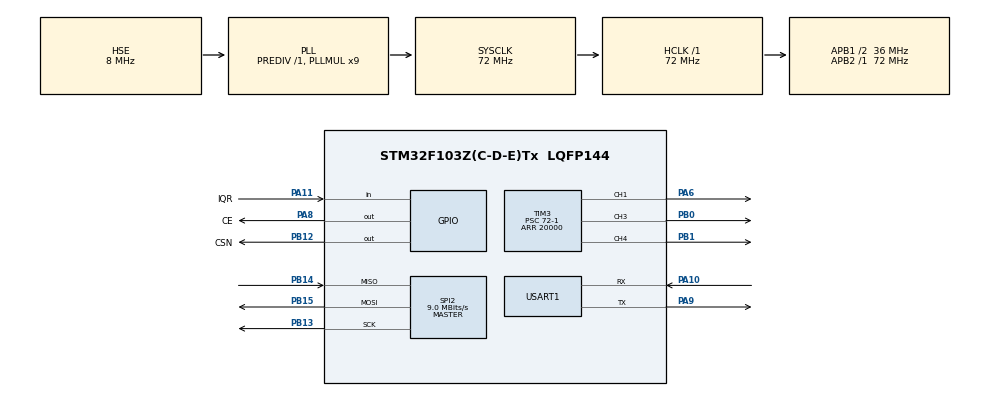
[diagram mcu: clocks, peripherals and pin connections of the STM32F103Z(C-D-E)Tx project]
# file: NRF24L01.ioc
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Mcu.Family=STM32F1
Mcu.Name=STM32F103Z(C-D-E)Tx
Mcu.Package=LQFP144
NVIC.PriorityGroup=NVIC_PRIORITYGROUP_4
OSC_IN.Mode=HSE-External-Oscillator
OSC_IN.Signal=RCC_OSC_IN
OSC_OUT.Mode=HSE-External-Oscillator
OSC_OUT.Signal=RCC_OSC_OUT
PA10.GPIO_PuPd=GPIO_NOPULL
PA10.Mode=Asynchronous
PA10.Signal=USART1_RX
PA11.GPIO_Label=IQR
PA11.Signal=GPIO_Input
PA13.Mode=Serial_Wire
PA13.Signal=SYS_JTMS-SWDIO
PA14.Mode=Serial_Wire
PA14.Signal=SYS_JTCK-SWCLK
PA6.Signal=S_TIM3_CH1
PA8.GPIO_Label=CE
PA8.GPIO_Speed=GPIO_SPEED_FREQ_HIGH
PA8.PinState=GPIO_PIN_SET
PA8.Signal=GPIO_Output
PA9.Mode=Asynchronous
PA9.Signal=USART1_TX
PB0.Signal=S_TIM3_CH3
PB1.Signal=S_TIM3_CH4
PB12.GPIO_Label=CSN
PB12.GPIO_ModeDefaultOutputPP=GPIO_MODE_OUTPUT_PP
PB12.GPIO_Speed=GPIO_SPEED_FREQ_HIGH
PB12.PinState=GPIO_PIN_SET
PB12.Signal=GPIO_Output
PB13.GPIO_Speed=GPIO_SPEED_FREQ_HIGH
PB13.Mode=Full_Duplex_Master
PB13.Signal=SPI2_SCK
PB14.GPIO_PuPd=GPIO_PULLUP
PB14.Mode=Full_Duplex_Master
PB14.Signal=SPI2_MISO
PB15.GPIO_Mode=GPIO_MODE_AF_PP
PB15.Mode=Full_Duplex_Master
PB15.Signal=SPI2_MOSI
ProjectManager.HeapSize=0x200
ProjectManager.StackSize=0x400
ProjectManager.TargetToolchain=MDK-ARM V5
RCC.ADCPresc=RCC_ADCPCLK2_DIV6
RCC.AHBFreq_Value=72000000
RCC.APB1CLKDivider=RCC_HCLK_DIV2
RCC.APB1Freq_Value=36000000
RCC.APB1TimFreq_Value=72000000
RCC.APB2Freq_Value=72000000
RCC.APB2TimFreq_Value=72000000
RCC.HCLKFreq_Value=72000000
RCC.PLLMUL=RCC_PLL_MUL9
RCC.PLLSourceVirtual=RCC_PLLSOURCE_HSE
RCC.SYSCLKFreq_VALUE=72000000
RCC.SYSCLKSource=RCC_SYSCLKSOURCE_PLLCLK
RCC.USBFreq_Value=72000000
SH.S_TIM3_CH1.0=TIM3_CH1,PWM Generation1 CH1
SH.S_TIM3_CH3.0=TIM3_CH3,PWM Generation3 CH3
SH.S_TIM3_CH4.0=TIM3_CH4,PWM Generation4 CH4
SPI2.BaudRatePrescaler=SPI_BAUDRATEPRESCALER_4
SPI2.CalculateBaudRate=9.0 MBits/s
SPI2.Direction=SPI_DIRECTION_2LINES
SPI2.Mode=SPI_MODE_MASTER
SPI2.VirtualType=VM_MASTER
TIM3.AutoReloadPreload=TIM_AUTORELOAD_PRELOAD_ENABLE
TIM3.Channel-PWM\ Generation1\ CH1=TIM_CHANNEL_1
TIM3.Channel-PWM\ Generation3\ CH3=TIM_CHANNEL_3
TIM3.Channel-PWM\ Generation4\ CH4=TIM_CHANNEL_4
TIM3.Period=20000
TIM3.Prescaler=72-1
USART1.VirtualMode=VM_ASYNC
board=NRF24L01

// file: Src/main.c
/**
  ******************************************************************************
  * File Name          : main.c
  * Description        : Main program body
  ******************************************************************************
  ** This notice applies to any and all portions of this file
  * that are not between comment pairs USER CODE BEGIN and
  * USER CODE END. Other portions of this file, whether
  * inserted by the user or by software development tools
  * are owned by their respective copyright owners.
  *
  * COPYRIGHT(c) 2017 STMicroelectronics
  *
  * Redistribution and use in source and binary forms, with or without modification,
  * are permitted provided that the following conditions are met:
  *   1. Redistributions of source code must retain the above copyright notice,
  *      this list of conditions and the following disclaimer.
  *   2. Redistributions in binary form must reproduce the above copyright notice,
  *      this list of conditions and the following disclaimer in the documentation
  *      and/or other materials provided with the distribution.
  *   3. Neither the name of STMicroelectronics nor the names of its contributors
  *      may be used to endorse or promote products derived from this software
  *      without specific prior written permission.
  *
  * THIS SOFTWARE IS PROVIDED BY THE COPYRIGHT HOLDERS AND CONTRIBUTORS "AS IS"
  * AND ANY EXPRESS OR IMPLIED WARRANTIES, INCLUDING, BUT NOT LIMITED TO, THE
  * IMPLIED WARRANTIES OF MERCHANTABILITY AND FITNESS FOR A PARTICULAR PURPOSE ARE
  * DISCLAIMED. IN NO EVENT SHALL THE COPYRIGHT HOLDER OR CONTRIBUTORS BE LIABLE
  * FOR ANY DIRECT, INDIRECT, INCIDENTAL, SPECIAL, EXEMPLARY, OR CONSEQUENTIAL
  * DAMAGES (INCLUDING, BUT NOT LIMITED TO, PROCUREMENT OF SUBSTITUTE GOODS OR
  * SERVICES; LOSS OF USE, DATA, OR PROFITS; OR BUSINESS INTERRUPTION) HOWEVER
  * CAUSED AND ON ANY THEORY OF LIABILITY, WHETHER IN CONTRACT, STRICT LIABILITY,
  * OR TORT (INCLUDING NEGLIGENCE OR OTHERWISE) ARISING IN ANY WAY OUT OF THE USE
  * OF THIS SOFTWARE, EVEN IF ADVISED OF THE POSSIBILITY OF SUCH DAMAGE.
  *
  ******************************************************************************
  */

#include "main.h"
#include "stm32f1xx_hal.h"
#include "spi.h"
#include "tim.h"
#include "usart.h"
#include "gpio.h"

/* USER CODE BEGIN Includes */
#include "nrf24l01.h"
#include "oled.h"
#include "feiji.h"

/* USER CODE END Includes */

/* USER CODE BEGIN PV */
/* Private variables ---------------------------------------------------------*/
uint8_t receive_value[6];
uint32_t trans_value[3];

/* USER CODE END PV */

void SystemClock_Config(void);

/* USER CODE BEGIN PFP */
/* Private function prototypes -----------------------------------------------*/

/* USER CODE END PFP */

int main(void)
{

  /* MCU Configuration----------------------------------------------------------*/

  /* Reset of all peripherals, Initializes the Flash interface and the Systick. */
  HAL_Init();

  /* USER CODE BEGIN Init */
	OLED_Init();
	OLED_Clear();

  /* USER CODE END Init */

  /* Configure the system clock */
  SystemClock_Config();

  /* Initialize all configured peripherals */
  MX_GPIO_Init();
  MX_USART1_UART_Init();
  MX_SPI2_Init();
  MX_TIM3_Init();

  /* USER CODE BEGIN 2 */
	PWM_Init();
	cheak_nrf();

  /* USER CODE END 2 */

  /* Infinite loop */
  while (1)
  {

  /* USER CODE BEGIN 3 */
		data_deal();
  }
  /* USER CODE END 3 */

}

/** System Clock Configuration
*/
void SystemClock_Config(void)
{

  RCC_OscInitTypeDef RCC_OscInitStruct;
  RCC_ClkInitTypeDef RCC_ClkInitStruct;

    /**Initializes the CPU, AHB and APB busses clocks
    */
  RCC_OscInitStruct.OscillatorType = RCC_OSCILLATORTYPE_HSE;
  RCC_OscInitStruct.HSEState = RCC_HSE_ON;
  RCC_OscInitStruct.HSEPredivValue = RCC_HSE_PREDIV_DIV1;
  RCC_OscInitStruct.HSIState = RCC_HSI_ON;
  RCC_OscInitStruct.PLL.PLLState = RCC_PLL_ON;
  RCC_OscInitStruct.PLL.PLLSource = RCC_PLLSOURCE_HSE;
  RCC_OscInitStruct.PLL.PLLMUL = RCC_PLL_MUL9;
  if (HAL_RCC_OscConfig(&RCC_OscInitStruct) != HAL_OK)
  {
    _Error_Handler(__FILE__, __LINE__);
  }

    /**Initializes the CPU, AHB and APB busses clocks
    */
  RCC_ClkInitStruct.ClockType = RCC_CLOCKTYPE_HCLK|RCC_CLOCKTYPE_SYSCLK
                              |RCC_CLOCKTYPE_PCLK1|RCC_CLOCKTYPE_PCLK2;
  RCC_ClkInitStruct.SYSCLKSource = RCC_SYSCLKSOURCE_PLLCLK;
  RCC_ClkInitStruct.AHBCLKDivider = RCC_SYSCLK_DIV1;
  RCC_ClkInitStruct.APB1CLKDivider = RCC_HCLK_DIV2;
  RCC_ClkInitStruct.APB2CLKDivider = RCC_HCLK_DIV1;

  if (HAL_RCC_ClockConfig(&RCC_ClkInitStruct, FLASH_LATENCY_2) != HAL_OK)
  {
    _Error_Handler(__FILE__, __LINE__);
  }

    /**Configure the Systick interrupt time
    */
  HAL_SYSTICK_Config(HAL_RCC_GetHCLKFreq()/1000);

    /**Configure the Systick
    */
  HAL_SYSTICK_CLKSourceConfig(SYSTICK_CLKSOURCE_HCLK);

  /* SysTick_IRQn interrupt configuration */
  HAL_NVIC_SetPriority(SysTick_IRQn, 0, 0);
}

void _Error_Handler(char * file, int line)
{
  while(1)
  {
  }
}

/************************ (C) COPYRIGHT STMicroelectronics *****END OF FILE****/
